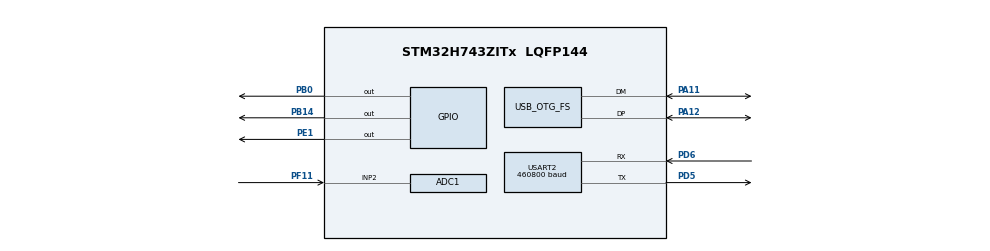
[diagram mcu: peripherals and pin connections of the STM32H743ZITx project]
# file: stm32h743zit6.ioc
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ADC1.Channel-0\#ChannelRegularConversion=ADC_CHANNEL_2
ADC1.ContinuousConvMode=ENABLE
ADC1.ConversionDataManagement=ADC_CONVERSIONDATA_DMA_CIRCULAR
ADC1.NbrOfConversionFlag=1
ADC1.OffsetNumber-0\#ChannelRegularConversion=ADC_OFFSET_NONE
ADC1.OffsetSignedSaturation-0\#ChannelRegularConversion=DISABLE
ADC1.Rank-0\#ChannelRegularConversion=1
ADC1.SamplingTime-0\#ChannelRegularConversion=ADC_SAMPLETIME_810CYCLES_5
ADC1.master=1
CORTEX_M7.default_mode_Activation=1
Dma.ADC1.0.Direction=DMA_PERIPH_TO_MEMORY
Dma.ADC1.0.EventEnable=DISABLE
Dma.ADC1.0.FIFOMode=DMA_FIFOMODE_DISABLE
Dma.ADC1.0.Instance=DMA1_Stream0
Dma.ADC1.0.MemDataAlignment=DMA_MDATAALIGN_HALFWORD
Dma.ADC1.0.MemInc=DMA_MINC_ENABLE
Dma.ADC1.0.Mode=DMA_CIRCULAR
Dma.ADC1.0.PeriphDataAlignment=DMA_PDATAALIGN_HALFWORD
Dma.ADC1.0.PeriphInc=DMA_PINC_DISABLE
Dma.ADC1.0.Polarity=HAL_DMAMUX_REQ_GEN_RISING
Dma.ADC1.0.Priority=DMA_PRIORITY_VERY_HIGH
Dma.ADC1.0.RequestNumber=1
Dma.ADC1.0.SignalID=NONE
Dma.ADC1.0.SyncEnable=DISABLE
Dma.ADC1.0.SyncPolarity=HAL_DMAMUX_SYNC_NO_EVENT
Dma.ADC1.0.SyncRequestNumber=1
Dma.ADC1.0.SyncSignalID=NONE
Dma.Request0=ADC1
Dma.Request1=USART2_RX
Dma.Request2=USART2_TX
Dma.USART2_RX.1.Direction=DMA_PERIPH_TO_MEMORY
Dma.USART2_RX.1.EventEnable=DISABLE
Dma.USART2_RX.1.FIFOMode=DMA_FIFOMODE_DISABLE
Dma.USART2_RX.1.Instance=DMA1_Stream1
Dma.USART2_RX.1.MemDataAlignment=DMA_MDATAALIGN_BYTE
Dma.USART2_RX.1.MemInc=DMA_MINC_ENABLE
Dma.USART2_RX.1.Mode=DMA_NORMAL
Dma.USART2_RX.1.PeriphDataAlignment=DMA_PDATAALIGN_BYTE
Dma.USART2_RX.1.PeriphInc=DMA_PINC_DISABLE
Dma.USART2_RX.1.Polarity=HAL_DMAMUX_REQ_GEN_RISING
Dma.USART2_RX.1.Priority=DMA_PRIORITY_LOW
Dma.USART2_RX.1.RequestNumber=1
Dma.USART2_RX.1.SignalID=NONE
Dma.USART2_RX.1.SyncEnable=DISABLE
Dma.USART2_RX.1.SyncPolarity=HAL_DMAMUX_SYNC_NO_EVENT
Dma.USART2_RX.1.SyncRequestNumber=1
Dma.USART2_RX.1.SyncSignalID=NONE
Dma.USART2_TX.2.Direction=DMA_MEMORY_TO_PERIPH
Dma.USART2_TX.2.EventEnable=DISABLE
Dma.USART2_TX.2.FIFOMode=DMA_FIFOMODE_DISABLE
Dma.USART2_TX.2.Instance=DMA1_Stream2
Dma.USART2_TX.2.MemDataAlignment=DMA_MDATAALIGN_BYTE
Dma.USART2_TX.2.MemInc=DMA_MINC_ENABLE
Dma.USART2_TX.2.Mode=DMA_NORMAL
Dma.USART2_TX.2.PeriphDataAlignment=DMA_PDATAALIGN_BYTE
Dma.USART2_TX.2.PeriphInc=DMA_PINC_DISABLE
Dma.USART2_TX.2.Polarity=HAL_DMAMUX_REQ_GEN_RISING
Dma.USART2_TX.2.Priority=DMA_PRIORITY_LOW
Dma.USART2_TX.2.RequestNumber=1
Dma.USART2_TX.2.SignalID=NONE
Dma.USART2_TX.2.SyncEnable=DISABLE
Dma.USART2_TX.2.SyncPolarity=HAL_DMAMUX_SYNC_NO_EVENT
Dma.USART2_TX.2.SyncRequestNumber=1
Dma.USART2_TX.2.SyncSignalID=NONE
Mcu.Family=STM32H7
Mcu.Name=STM32H743ZITx
Mcu.Package=LQFP144
NVIC.DMA1_Stream0_IRQn=true\:0\:0\:false\:false\:true\:false\:true\:true
NVIC.DMA1_Stream1_IRQn=true\:0\:0\:false\:false\:true\:false\:true\:true
NVIC.DMA1_Stream2_IRQn=true\:0\:0\:false\:false\:true\:false\:true\:true
NVIC.OTG_FS_IRQn=true\:0\:0\:false\:false\:true\:false\:true\:true
NVIC.PriorityGroup=NVIC_PRIORITYGROUP_4
NVIC.TIM2_IRQn=true\:0\:0\:false\:false\:true\:true\:true\:true
NVIC.TIM3_IRQn=true\:0\:0\:false\:false\:true\:true\:true\:true
NVIC.TIM4_IRQn=true\:0\:0\:false\:false\:true\:true\:true\:true
NVIC.USART2_IRQn=true\:0\:0\:false\:false\:true\:false\:true\:true
PA11.Mode=Device_Only
PA11.Signal=USB_OTG_FS_DM
PA12.Mode=Device_Only
PA12.Signal=USB_OTG_FS_DP
PA13\ (JTMS/SWDIO).Mode=Serial_Wire
PA13\ (JTMS/SWDIO).Signal=DEBUG_JTMS-SWDIO
PA14\ (JTCK/SWCLK).Mode=Serial_Wire
PA14\ (JTCK/SWCLK).Signal=DEBUG_JTCK-SWCLK
PB0.Signal=GPIO_Output
PB14.Signal=GPIO_Output
PD5.Mode=Asynchronous
PD5.Signal=USART2_TX
PD6.Mode=Asynchronous
PD6.Signal=USART2_RX
PE1.Signal=GPIO_Output
PF11.Mode=IN2-Single-Ended
PF11.Signal=ADC1_INP2
ProjectManager.HeapSize=0x800
ProjectManager.StackSize=0x400
ProjectManager.TargetToolchain=CMake
RCC.ADCFreq_Value=80000000
RCC.APB1Freq_Value=40000000
RCC.APB2Freq_Value=80000000
RCC.APB3Freq_Value=80000000
RCC.APB4Freq_Value=80000000
RCC.CortexFreq_Value=80000000
RCC.D2PPRE1=RCC_APB1_DIV2
RCC.DIVM1=4
RCC.DIVM2=4
RCC.DIVN1=10
RCC.DIVN2=10
RCC.HCLKFreq_Value=80000000
RCC.PLL2FRACN=0
RCC.PLL3FRACN=0
RCC.PLLFRACN=0
RCC.SYSCLKFreq_VALUE=80000000
RCC.SYSCLKSource=RCC_SYSCLKSOURCE_PLLCLK
RCC.USBCLockSelection=RCC_USBCLKSOURCE_HSI48
RCC.USBFreq_Value=48000000
USART2.BaudRate=460800
USART2.VirtualMode-Asynchronous=VM_ASYNC
USB_DEVICE.CLASS_NAME_FS=CDC
USB_DEVICE.VirtualMode-CDC_FS=Cdc
USB_DEVICE.VirtualModeFS=Cdc_FS
USB_OTG_FS.VirtualMode=Device_Only
VP_MEMORYMAP_VS_MEMORYMAP.Mode=CurAppReg
VP_TIM2_VS_ClockSourceINT.Mode=Internal
VP_TIM3_VS_ClockSourceINT.Mode=Internal
VP_TIM4_VS_ClockSourceINT.Mode=Internal
VP_USB_DEVICE_VS_USB_DEVICE_CDC_FS.Mode=CDC_FS
board=custom

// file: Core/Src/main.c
/* USER CODE BEGIN Header */
/**
 ******************************************************************************
 * @file           : main.c
 * @brief          : Main program body
 ******************************************************************************
 * @attention
 *
 * Copyright (c) 2025 STMicroelectronics.
 * All rights reserved.
 *
 * This software is licensed under terms that can be found in the LICENSE file
 * in the root directory of this software component.
 * If no LICENSE file comes with this software, it is provided AS-IS.
 *
 ******************************************************************************
 */
/* USER CODE END Header */
#include "main.h"
#include "adc.h"
#include "dma.h"
#include "tim.h"
#include "usart.h"
#include "usb_device.h"
#include "gpio.h"

/* USER CODE BEGIN Includes */
#include "_h743_hals.h"
#include "u_comm.h"
/* USER CODE END Includes */

/* USER CODE BEGIN PV */
extern UART_HandleTypeDef huart2;
u_comm_t *g_comm;

/* USER CODE END PV */

void SystemClock_Config(void);
static void MPU_Config(void);

int main(void)
{

  /* MPU Configuration--------------------------------------------------------*/
  MPU_Config();

  /* MCU Configuration--------------------------------------------------------*/

  /* Reset of all peripherals, Initializes the Flash interface and the Systick. */
  HAL_Init();

  /* Configure the system clock */
  SystemClock_Config();

  /* Initialize all configured peripherals */
  MX_GPIO_Init();
  MX_DMA_Init();
  MX_ADC1_Init();
  MX_TIM2_Init();
  MX_TIM3_Init();
  MX_TIM4_Init();
  MX_USB_DEVICE_Init();
  MX_USART2_UART_Init();
  /* USER CODE BEGIN 2 */
  g_comm = u_comm_init(&huart2, 460800, 1);
  /* USER CODE END 2 */

  /* Infinite loop */
  while (1)
  {

    /* USER CODE BEGIN 3 */
    uint16_t packet_size = sizeof(*g_comm->_m_packet);
    g_comm->_m_packet->m_cs = checksum((uint8_t *)g_comm->_m_packet, packet_size - 1);
    memcpy(g_comm->_m_uart->m_tx_buffer, g_comm->_m_packet, packet_size);
    g_comm->_m_uart->_h743_uart_send(g_comm->_m_uart);

    _h743_hal_delay_ms(1);
  }
  /* USER CODE END 3 */
}

void SystemClock_Config(void)
{
  RCC_OscInitTypeDef RCC_OscInitStruct = {0};
  RCC_ClkInitTypeDef RCC_ClkInitStruct = {0};

  /** Supply configuration update enable
  */
  HAL_PWREx_ConfigSupply(PWR_LDO_SUPPLY);

  /** Configure the main internal regulator output voltage
  */
  __HAL_PWR_VOLTAGESCALING_CONFIG(PWR_REGULATOR_VOLTAGE_SCALE3);

  while(!__HAL_PWR_GET_FLAG(PWR_FLAG_VOSRDY)) {}

  /** Initializes the RCC Oscillators according to the specified parameters
  * in the RCC_OscInitTypeDef structure.
  */
  RCC_OscInitStruct.OscillatorType = RCC_OSCILLATORTYPE_HSI48|RCC_OSCILLATORTYPE_HSI;
  RCC_OscInitStruct.HSIState = RCC_HSI_DIV1;
  RCC_OscInitStruct.HSICalibrationValue = RCC_HSICALIBRATION_DEFAULT;
  RCC_OscInitStruct.HSI48State = RCC_HSI48_ON;
  RCC_OscInitStruct.PLL.PLLState = RCC_PLL_ON;
  RCC_OscInitStruct.PLL.PLLSource = RCC_PLLSOURCE_HSI;
  RCC_OscInitStruct.PLL.PLLM = 4;
  RCC_OscInitStruct.PLL.PLLN = 10;
  RCC_OscInitStruct.PLL.PLLP = 2;
  RCC_OscInitStruct.PLL.PLLQ = 2;
  RCC_OscInitStruct.PLL.PLLR = 2;
  RCC_OscInitStruct.PLL.PLLRGE = RCC_PLL1VCIRANGE_3;
  RCC_OscInitStruct.PLL.PLLVCOSEL = RCC_PLL1VCOMEDIUM;
  RCC_OscInitStruct.PLL.PLLFRACN = 0;
  if (HAL_RCC_OscConfig(&RCC_OscInitStruct) != HAL_OK)
  {
    Error_Handler();
  }

  /** Initializes the CPU, AHB and APB buses clocks
  */
  RCC_ClkInitStruct.ClockType = RCC_CLOCKTYPE_HCLK|RCC_CLOCKTYPE_SYSCLK
                              |RCC_CLOCKTYPE_PCLK1|RCC_CLOCKTYPE_PCLK2
                              |RCC_CLOCKTYPE_D3PCLK1|RCC_CLOCKTYPE_D1PCLK1;
  RCC_ClkInitStruct.SYSCLKSource = RCC_SYSCLKSOURCE_PLLCLK;
  RCC_ClkInitStruct.SYSCLKDivider = RCC_SYSCLK_DIV1;
  RCC_ClkInitStruct.AHBCLKDivider = RCC_HCLK_DIV1;
  RCC_ClkInitStruct.APB3CLKDivider = RCC_APB3_DIV1;
  RCC_ClkInitStruct.APB1CLKDivider = RCC_APB1_DIV2;
  RCC_ClkInitStruct.APB2CLKDivider = RCC_APB2_DIV1;
  RCC_ClkInitStruct.APB4CLKDivider = RCC_APB4_DIV1;

  if (HAL_RCC_ClockConfig(&RCC_ClkInitStruct, FLASH_LATENCY_1) != HAL_OK)
  {
    Error_Handler();
  }
}

 /* MPU Configuration */

void MPU_Config(void)
{
  MPU_Region_InitTypeDef MPU_InitStruct = {0};

  /* Disables the MPU */
  HAL_MPU_Disable();

  /** Initializes and configures the Region and the memory to be protected
  */
  MPU_InitStruct.Enable = MPU_REGION_ENABLE;
  MPU_InitStruct.Number = MPU_REGION_NUMBER0;
  MPU_InitStruct.BaseAddress = 0x0;
  MPU_InitStruct.Size = MPU_REGION_SIZE_4GB;
  MPU_InitStruct.SubRegionDisable = 0x87;
  MPU_InitStruct.TypeExtField = MPU_TEX_LEVEL0;
  MPU_InitStruct.AccessPermission = MPU_REGION_NO_ACCESS;
  MPU_InitStruct.DisableExec = MPU_INSTRUCTION_ACCESS_DISABLE;
  MPU_InitStruct.IsShareable = MPU_ACCESS_SHAREABLE;
  MPU_InitStruct.IsCacheable = MPU_ACCESS_NOT_CACHEABLE;
  MPU_InitStruct.IsBufferable = MPU_ACCESS_NOT_BUFFERABLE;

  HAL_MPU_ConfigRegion(&MPU_InitStruct);
  /* Enables the MPU */
  HAL_MPU_Enable(MPU_PRIVILEGED_DEFAULT);

}

void Error_Handler(void)
{
  __disable_irq();
  while (1)
  {
  }
}
